# MKW38A4 register map
Vendor: NXP Semiconductors; Series: Kinetis_W; File version: 1.6
CPU: CM0PLUS r0p0, little endian, no MPU, no FPU, VTOR, 2 interrupt priority bits
Registers are 32-bit, read-write, no defined reset value unless marked. A register's access mark holds for its fields unless they carry their own. Offsets are from the block's base; [hi:lo] are bit positions; {n}, {i} and the like mark numbered series; 'fields as' and 'values as' point back to an identical list.

## XCVR_RX_DIG
Base 0x40087000
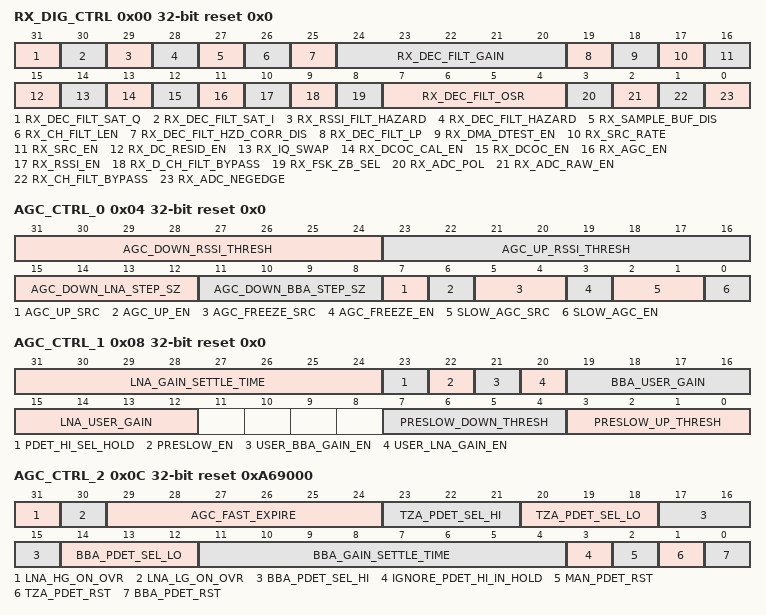
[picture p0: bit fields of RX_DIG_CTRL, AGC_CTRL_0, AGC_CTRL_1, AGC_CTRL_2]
0x00 RX_DIG_CTRL reset 0x0 — RX Digital Control
  [31] RX_DEC_FILT_SAT_Q ro — Decimator output, saturation detected for Q channel
    0=A saturation condition has not occurred; 1=A saturation condition has occurred
  [30] RX_DEC_FILT_SAT_I ro — Decimator output, saturation detected for I channel
    values as RX_DEC_FILT_SAT_Q
  [29] RX_RSSI_FILT_HAZARD ro — Decimator output for RSSI, hazard condition detected
    0=A hazard condition has not been detected; 1=A hazard condition has been detected
  [28] RX_DEC_FILT_HAZARD ro — Decimator output, hazard condition detected
    values as RX_RSSI_FILT_HAZARD
  [27] RX_SAMPLE_BUF_DIS — RX Sample Buffer Disable
    0=Buffer is enabled; 1=Buffer is disabled
  [26] RX_CH_FILT_LEN — RX Channel Filter Length
    0=Channel filter length is 24; 1=Channel filter length is 16. Only RX_CHF_COEF_4 - RX_CHF_COEF_11 are used in this mode.
  [25] RX_DEC_FILT_HZD_CORR_DIS — Decimator filter hazard correction disable
    0=Hazard correction is enabled; 1=Hazard correction is disabled
  [24:20] RX_DEC_FILT_GAIN — Decimation Filter Fractional Gain
  [19] RX_DEC_FILT_LP — RX Decimator Low Power
    0=Decimator operates in normal mode; 1=Decimator operates in low power mode
  [18] RX_DMA_DTEST_EN — RX DMA and DTEST enable
  [17] RX_SRC_RATE — RX Sample Rate Converter Rate Selections
    0=SRC is configured for a First Order Hold rate of 8/13; 1=SRC is configured for a Zero Order Hold rate of 12/13
  [16] RX_SRC_EN — RX Sample Rate Converter Enable
    0=SRC is disabled; 1=SRC is enabled
  [15] RX_DC_RESID_EN — DC Residual Enable
    0=DC Residual block is disabled; 1=DC Residual block is enabled
  [14] RX_IQ_SWAP
    0=IQ swap is disabled; 1=IQ swap is enabled
  [13] RX_DCOC_CAL_EN — DCOC Calibration Enable
    0=DCOC calibration is disabled; 1=DCOC calibration is enabled
  [12] RX_DCOC_EN — DCOC Enable
    0=DCOC is disabled; 1=DCOC is enabled
  [11] RX_AGC_EN — AGC Global Enable
    0=AGC is disabled; 1=AGC is enabled
  [10] RX_RSSI_EN — RSSI Measurement Enable
    0=RSSI measurement is disabled; 1=RSSI measurement is enabled
  [9] RX_D_CH_FILT_BYPASS — Receive Demod Channel Filter Bypass
    0=Demod channel filter is enabled; 1=Disable and bypass demod channel filter
  [8] RX_FSK_ZB_SEL — Demodulator select
    0=FSK demodulator
  [7:4] RX_DEC_FILT_OSR — Decimation Filter Oversampling
    0=OSR 4; 1=OSR 8; 2=OSR 16; 4=OSR 32; 8=OSR 64; 3=OSR 6; 5=OSR 12; 6=OSR 24; 7=OSR 48
  [3] RX_ADC_POL — Receive ADC Polarity
    0=ADC output of 1'b0 maps to -1, 1'b1 maps to +1 (default); 1=ADC output of 1'b0 maps to +1, 1'b1 maps to -1
  [2] RX_ADC_RAW_EN — ADC Raw Mode selection
    0=Normal operation; 1=The decimation filter's 12bit output consists of ADC samples in the 8 LSBs. This is for test purposes only to observe ADC output via XCVR DMA or DTEST.
  [1] RX_CH_FILT_BYPASS — Receive Channel Filter Bypass
    0=Channel filter is enabled; 1=Disable and bypass channel filter
  [0] RX_ADC_NEGEDGE — Receive ADC Negative Edge Selection
    0=Register ADC data on positive edge of clock; 1=Register ADC data on negative edge of clock
0x04 AGC_CTRL_0 reset 0x0 — AGC Control 0
  [31:24] AGC_DOWN_RSSI_THRESH — AGC DOWN RSSI Threshold
  [23:16] AGC_UP_RSSI_THRESH — AGC UP RSSI Threshold
  [15:12] AGC_DOWN_LNA_STEP_SZ
  [11:8] AGC_DOWN_BBA_STEP_SZ
  [7] AGC_UP_SRC — AGC Up Source
    0=PDET LO; 1=RSSI
  [6] AGC_UP_EN — AGC Up Enable
  [5:4] AGC_FREEZE_SRC — AGC Freeze Source Selection
    0=Access Address match (for active protocol); 1=Preamble Detect (for active protocol); 2=PD confirmation / Access Address match (for active protocol)
  [3] AGC_FREEZE_EN — AGC Freeze Enable
  [2:1] SLOW_AGC_SRC — Slow AGC Source Selection
    0=Access Address match (for active protocol); 1=Preamble Detect (for active protocol); 2=Fast AGC expire timer
  [0] SLOW_AGC_EN — Slow AGC Enable
0x08 AGC_CTRL_1 reset 0x0 — AGC Control 1
  [31:24] LNA_GAIN_SETTLE_TIME
  [23] PDET_HI_SEL_HOLD — AGC HOLD hysteresis
    0=Disabled; 1=Enabled
  [22] PRESLOW_EN — Pre-slow Enable
    0=Pre-slow is disabled; 1=Pre-slow is enabled
  [21] USER_BBA_GAIN_EN — User BBA Gain Enable
  [20] USER_LNA_GAIN_EN — User LNA Gain Enable
  [19:16] BBA_USER_GAIN
  [15:12] LNA_USER_GAIN
  [7:4] PRESLOW_DOWN_THRESH
  [3:0] PRESLOW_UP_THRESH
0x0C AGC_CTRL_2 reset 0xA69000 — AGC Control 2
  [31] LNA_HG_ON_OVR — LNA_HG_ON override
  [30] LNA_LG_ON_OVR — LNA_LG_ON override
  [29:24] AGC_FAST_EXPIRE
  [23:21] TZA_PDET_SEL_HI — TZA PDET Threshold High
    0=0.600V; 1=0.645V; 2=0.705V; 3=0.750V; 4=0.795V; 5=0.855V; 6=0.900V; 7=0.945V
  [20:18] TZA_PDET_SEL_LO — TZA PDET Threshold Low
    0=0.600V; 1=0.615V; 2=0.630V; 3=0.645V; 4=0.660V; 5=0.675V; 6=0.690V; 7=0.705V
  [17:15] BBA_PDET_SEL_HI — BBA PDET Threshold High
    0=0.600V; 1=0.795V; 2=0.900V; 3=0.945V; 4=1.005V; 5=1.050V; 6=1.095V; 7=1.155V
  [14:12] BBA_PDET_SEL_LO — BBA PDET Threshold Low
    values as TZA_PDET_SEL_LO
  [11:4] BBA_GAIN_SETTLE_TIME
  [3] IGNORE_PDET_HI_IN_HOLD — Ignore PDET_HI in HOLD State
  [2] MAN_PDET_RST — MAN PDET Reset
    0=The peak detector reset signals are controlled automatically by the AGC; 1=The BBA_PDET_RST and TZA_PDET_RST are used to manually control the peak detector reset signals
  [1] TZA_PDET_RST — TZA PDET Reset
  [0] BBA_PDET_RST — BBA PDET Reset
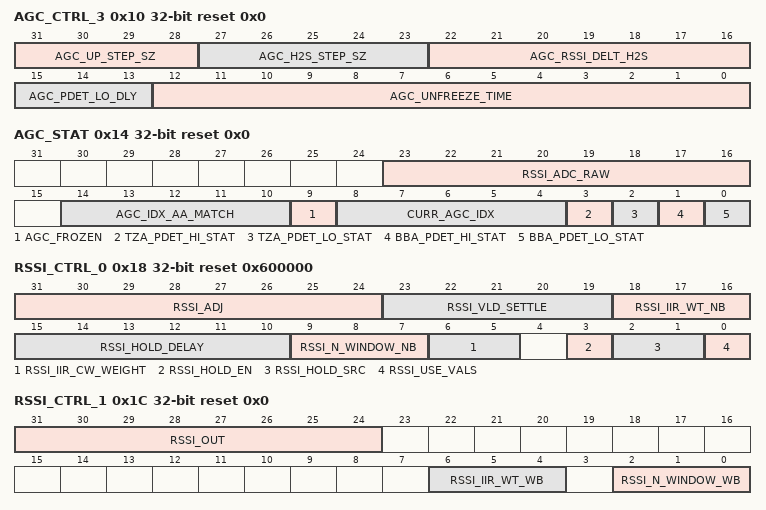
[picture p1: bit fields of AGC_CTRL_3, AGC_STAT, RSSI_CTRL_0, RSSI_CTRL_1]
0x10 AGC_CTRL_3 reset 0x0 — AGC Control 3
  [31:28] AGC_UP_STEP_SZ — AGC Up Step Size
  [27:23] AGC_H2S_STEP_SZ
  [22:16] AGC_RSSI_DELT_H2S
  [15:13] AGC_PDET_LO_DLY — AGC Peak Detect Low Delay
  [12:0] AGC_UNFREEZE_TIME
0x14 AGC_STAT ro reset 0x0 — AGC Status
  [23:16] RSSI_ADC_RAW — ADC RAW RSSI Reading
  [14:10] AGC_IDX_AA_MATCH — AGC Gain Index at AA Match
  [9] AGC_FROZEN — AGC Frozen Status
    0=AGC is not frozen; 1=AGC is frozen
  [8:4] CURR_AGC_IDX — Current AGC Gain Index
  [3] TZA_PDET_HI_STAT — TZA Peak Detector High Status
  [2] TZA_PDET_LO_STAT — TZA Peak Detector Low Status
  [1] BBA_PDET_HI_STAT — BBA Peak Detector High Status
  [0] BBA_PDET_LO_STAT — BBA Peak Detector Low Status
0x18 RSSI_CTRL_0 reset 0x600000 — RSSI Control 0
  [31:24] RSSI_ADJ — RSSI Adjustment
  [23:19] RSSI_VLD_SETTLE — RSSI Valid Settle
  [18:16] RSSI_IIR_WT_NB — RSSI IIR Weighting Narrowband
    0=Bypass; 1=1/2; 2=1/4; 3=1/8; 4=1/16; 5=1/32
  [15:10] RSSI_HOLD_DELAY
  [9:7] RSSI_N_WINDOW_NB — RSSI N Window Average Narrowband
    0=No averaging; 1=Averaging window length is 2 samples; 2=Averaging window length is 4 samples; 3=Averaging window length is 8 samples; 4=Averaging window length is 16 samples; 5=Averaging window length is 32 samples
  [6:5] RSSI_IIR_CW_WEIGHT — RSSI IIR CW Weighting
    0=Bypass; 1=1/8; 2=1/16; 3=1/32
  [3] RSSI_HOLD_EN — RSSI Hold Enable
  [2:1] RSSI_HOLD_SRC — RSSI Hold Source Selection
    0=Access Address match; 1=Preamble Detect
  [0] RSSI_USE_VALS — RSSI Values Selection
    0=RSSI calculation uses BBA_RES_TUNE_VAL registers; 1=RSSI calculation does not use BBA_RES_TUNE_VAL registers
0x1C RSSI_CTRL_1 reset 0x0 — RSSI Control 1
  [31:24] RSSI_OUT ro — RSSI Reading
  [6:4] RSSI_IIR_WT_WB — RSSI IIR Weighting Wideband
    0=Bypass; 1=1/2; 2=1/4; 3=1/8; 4=1/16; 5=1/32
  [2:0] RSSI_N_WINDOW_WB — RSSI N Window Average Wideband
    values as RSSI_CTRL_0.RSSI_N_WINDOW_NB
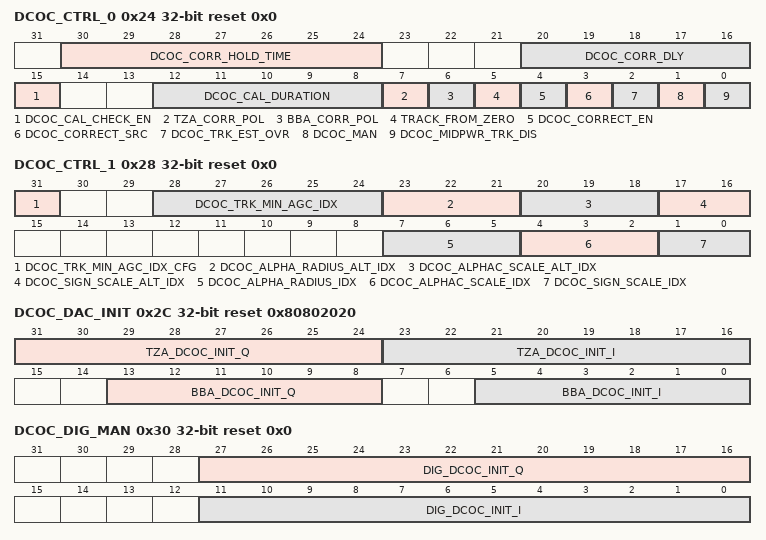
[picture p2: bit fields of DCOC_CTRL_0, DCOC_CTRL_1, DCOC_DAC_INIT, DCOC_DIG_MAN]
0x24 DCOC_CTRL_0 reset 0x0 — DCOC Control 0
  [30:24] DCOC_CORR_HOLD_TIME — DCOC Correction Hold Time
    127=The DC correction is not frozen
  [20:16] DCOC_CORR_DLY — DCOC Correction Delay
  [15] DCOC_CAL_CHECK_EN — DCOC Calibration Check Enable
    0=Calibration checking disabled. The DCOC_OFFSET_n registers are always updated during calibration.; 1=Calibration checking enabled. The DCOC_OFFSET_n registers are updated conditionally depending on the outcome of the pass/fail threshold checks performed on the alpha-hat and beta-hat estimates during calibration.
  [12:8] DCOC_CAL_DURATION — DCOC Calibration Duration
  [7] TZA_CORR_POL — TZA Correction Polarity
    0=Normal polarity; 1=Negative polarity. This should be set if the ADC output is inverted, or if the TZA DACs were implemented with negative polarity.
  [6] BBA_CORR_POL — BBA Correction Polarity
    0=Normal polarity; 1=Negative polarity. This should be set if the ADC output is inverted, or if the BBA DACs were implemented with negative polarity.
  [5] TRACK_FROM_ZERO
    0=Track from current I/Q sample; 1=Track from zero
  [4] DCOC_CORRECT_EN — DCOC Correction Enable
    0=Correction disabled. The DCOC will not correct the DC offset.; 1=Correction enabled. The DCOC will use the TZA and BBA DACs, and apply digital corrections (if DCOC_CORRECT_SRC=1) to correct the DC offset.
  [3] DCOC_CORRECT_SRC — DCOC Corrector Source
    0=If correction is enabled, the DCOC will use only the DCOC calibration table to correct the DC offset; 1=If correction is enabled, the DCOC will use the DCOC calibration table and then the tracking estimator to correct the DC offset
  [2] DCOC_TRK_EST_OVR — Override for the DCOC tracking estimator
    0=The tracking estimator is enabled only as needed by the corrector; 1=The tracking estimator remains enabled whenever the DCOC is active
  [1] DCOC_MAN — DCOC Manual Override
  [0] DCOC_MIDPWR_TRK_DIS — DCOC Mid Power Tracking Disable
    0=Tracking corrections are enabled as determined by DCOC_CORRECT_SRC and DCOC_TRK_MIN_AGC_IDX; 1=Tracking corrections are disabled when either the TZA or BBA lo peak detector asserts
0x28 DCOC_CTRL_1 reset 0x0 — DCOC Control 1
  [31] DCOC_TRK_MIN_AGC_IDX_CFG — DCOC_TRK_MIN_AGC_IDX Configuration
    0=Tracking is disabled when the AGC index is less than DCOC_TRK_MIN_AGC_IDX; 1=Tracking is enabled when AGC index is less than DCOC_TRK_MIN_AGC_IDX, but {DCOC_CORR_DLY_ALT, DCOC_CORR_HOLD_TIME_ALT, DCOC_ALPHA_RADIUS_ALT_IDX, DCOC_ALPHAC_SCALE_ALT_IDX, DCOC_SIGN_SCALE_ALT_IDX} are used instead of {DCOC_CORR_DLY, DCOC_CORR_HOLD_TIME, DCOC_ALPHA_RADIUS_IDX, DCOC_ALPHAC_SCALE_IDX, DCOC_SIGN_SCALE_IDX}
  [28:24] DCOC_TRK_MIN_AGC_IDX — DCOC Tracking Minimum AGC Table Index
  [23:21] DCOC_ALPHA_RADIUS_ALT_IDX — Alpha-R Scaling Alternate
    0=1; 1=1/2; 2=1/4; 3=1/8; 4=1/16; 5=1/32; 6=1/64
  [20:18] DCOC_ALPHAC_SCALE_ALT_IDX — DCOC Alpha-C Scaling Alternate
    0=1/2; 1=1/4; 2=1/8; 3=1/16; 4=1/32; 5=1/64
  [17:16] DCOC_SIGN_SCALE_ALT_IDX — DCOC Sign Scaling Alternate
    0=1/8; 1=1/16; 2=1/32; 3=1/64
  [7:5] DCOC_ALPHA_RADIUS_IDX — Alpha-R Scaling
    0=1; 1=1/2; 2=1/4; 3=1/8; 4=1/16; 5=1/32; 6=1/64
  [4:2] DCOC_ALPHAC_SCALE_IDX — DCOC Alpha-C Scaling
    0=1/2; 1=1/4; 2=1/8; 3=1/16; 4=1/32; 5=1/64
  [1:0] DCOC_SIGN_SCALE_IDX — DCOC Sign Scaling
    0=1/8; 1=1/16; 2=1/32; 3=1/64
0x2C DCOC_DAC_INIT reset 0x80802020 — DCOC DAC Initialization
  [31:24] TZA_DCOC_INIT_Q — DCOC TZA Init Q
  [23:16] TZA_DCOC_INIT_I — DCOC TZA Init I
  [13:8] BBA_DCOC_INIT_Q — DCOC BBA Init Q
  [5:0] BBA_DCOC_INIT_I — DCOC BBA Init I
0x30 DCOC_DIG_MAN reset 0x0 — DCOC Digital Correction Manual Override
  [27:16] DIG_DCOC_INIT_Q — DCOC DIG Init Q
  [11:0] DIG_DCOC_INIT_I — DCOC DIG Init I
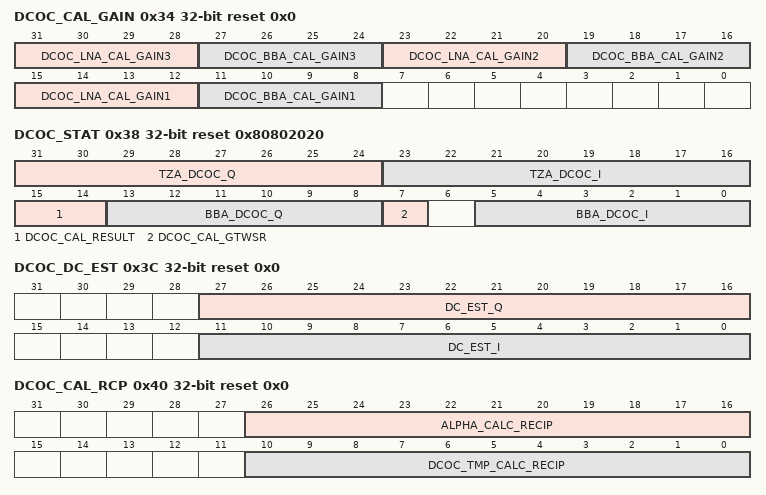
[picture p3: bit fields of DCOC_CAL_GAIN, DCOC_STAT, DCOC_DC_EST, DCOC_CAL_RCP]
0x34 DCOC_CAL_GAIN reset 0x0 — DCOC Calibration Gain
  [31:28] DCOC_LNA_CAL_GAIN3 — DCOC LNA Calibration Gain 3
  [27:24] DCOC_BBA_CAL_GAIN3 — DCOC BBA Calibration Gain 3
  [23:20] DCOC_LNA_CAL_GAIN2 — DCOC LNA Calibration Gain 2
  [19:16] DCOC_BBA_CAL_GAIN2 — DCOC BBA Calibration Gain 2
  [15:12] DCOC_LNA_CAL_GAIN1 — DCOC LNA Calibration Gain 1
  [11:8] DCOC_BBA_CAL_GAIN1 — DCOC BBA Calibration Gain 1
0x38 DCOC_STAT ro reset 0x80802020 — DCOC Status
  [31:24] TZA_DCOC_Q — DCOC TZA DAC Q
  [23:16] TZA_DCOC_I — DCOC TZA DAC I
  [15:14] DCOC_CAL_RESULT
    0=Calibration checks failed. DCOC_OFFSET_n tables not updated.; 1=Calibration checks neither passed nor failed, DCOC_OFFSET_n tables not updated; 2=Calibration checks neither passed nor failed, DCOC_OFFSET_n tables updated since no previous Pass condition has occurred since the last radio reset; 3=Calibration checks passed. DCOC_OFFSET_n tables updated
  [13:8] BBA_DCOC_Q — DCOC BBA DAC Q
  [7] DCOC_CAL_GTWSR — DCOC calibration Good Table Written Since Reset
    0=A Passing calibration result has not occurred since the last radio reset; 1=A Passing calibration result has occurred since the last radio reset
  [5:0] BBA_DCOC_I — DCOC BBA DAC I
0x3C DCOC_DC_EST ro reset 0x0 — DCOC DC Estimate
  [27:16] DC_EST_Q — DCOC DC Estimate Q
  [11:0] DC_EST_I — DCOC DC Estimate I
0x40 DCOC_CAL_RCP reset 0x0 — DCOC Calibration Reciprocals
  [26:16] ALPHA_CALC_RECIP — Alpha Calculation Reciprocal
  [10:0] DCOC_TMP_CALC_RECIP — DCOC Calculation Reciprocal
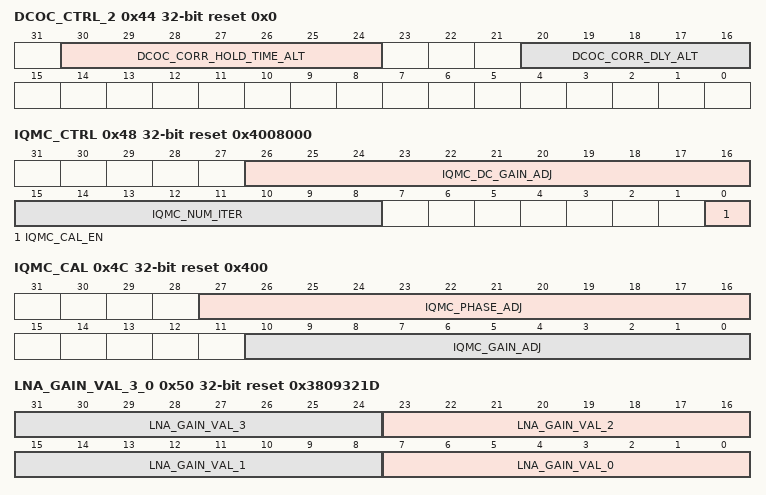
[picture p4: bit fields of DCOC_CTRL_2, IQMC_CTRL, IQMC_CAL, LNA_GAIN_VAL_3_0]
0x44 DCOC_CTRL_2 reset 0x0 — DCOC Control 2
  [30:24] DCOC_CORR_HOLD_TIME_ALT — DCOC Correction Hold Time Alternate
    127=The DC correction is not frozen
  [20:16] DCOC_CORR_DLY_ALT — DCOC Correction Delay Alternate
0x48 IQMC_CTRL reset 0x4008000 — IQMC Control
  [26:16] IQMC_DC_GAIN_ADJ — IQ Mismatch Correction DC Gain Coeff
  [15:8] IQMC_NUM_ITER — IQ Mismatch Cal Num Iter
  [0] IQMC_CAL_EN — IQ Mismatch Cal Enable
0x4C IQMC_CAL reset 0x400 — IQMC Calibration
  [27:16] IQMC_PHASE_ADJ — IQ Mismatch Correction Phase Coeff
  [10:0] IQMC_GAIN_ADJ — IQ Mismatch Correction Gain Coeff
0x50 LNA_GAIN_VAL_3_0 reset 0x3809321D — LNA_GAIN Step Values 3..0
  [8n+7:8n] LNA_GAIN_VAL_{n} (n=0..3) — LNA_GAIN step {n}
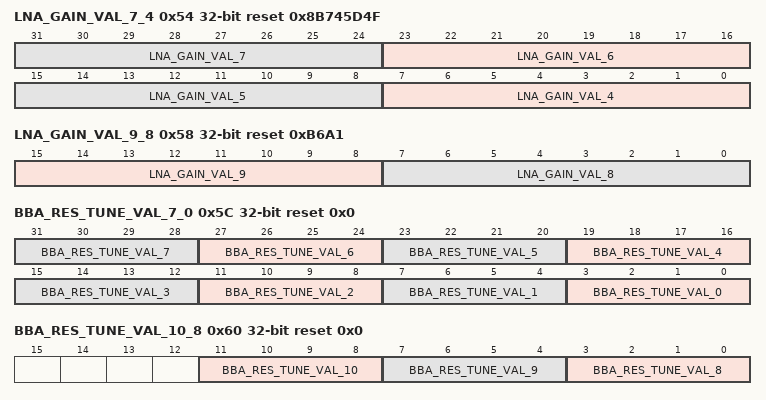
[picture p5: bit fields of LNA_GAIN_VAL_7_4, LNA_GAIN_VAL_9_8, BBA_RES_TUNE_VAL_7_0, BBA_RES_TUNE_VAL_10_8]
0x54 LNA_GAIN_VAL_7_4 reset 0x8B745D4F — LNA_GAIN Step Values 7..4
  [8n-25:8n-32] LNA_GAIN_VAL_{n} (n=4..7) — LNA_GAIN step {n}
0x58 LNA_GAIN_VAL_9_8 reset 0xB6A1 — LNA_GAIN Step Values 9..8
  [15:8] LNA_GAIN_VAL_9 — LNA_GAIN step 9
  [7:0] LNA_GAIN_VAL_8 — LNA_GAIN step 8
0x5C BBA_RES_TUNE_VAL_7_0 reset 0x0 — BBA Resistor Tune Values 7..0
  [4n+3:4n] BBA_RES_TUNE_VAL_{n} (n=0..7) — BBA Resistor Tune Step {n}
0x60 BBA_RES_TUNE_VAL_10_8 reset 0x0 — BBA Resistor Tune Values 10..8
  [11:8] BBA_RES_TUNE_VAL_10 — BBA Resistor Tune Step 10
  [7:4] BBA_RES_TUNE_VAL_9 — BBA Resistor Tune Step 9
  [3:0] BBA_RES_TUNE_VAL_8 — BBA Resistor Tune Step 8
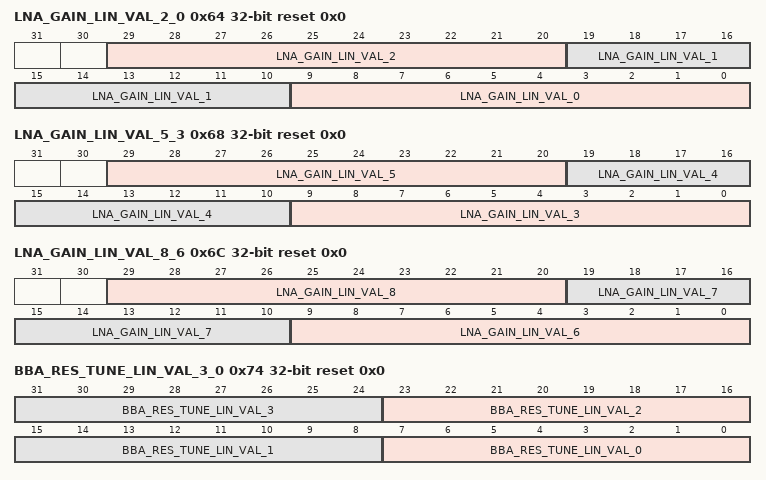
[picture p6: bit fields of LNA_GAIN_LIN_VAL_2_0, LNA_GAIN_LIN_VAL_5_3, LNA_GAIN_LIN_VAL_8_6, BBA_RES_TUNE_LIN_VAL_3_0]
0x64 LNA_GAIN_LIN_VAL_2_0 reset 0x0 — LNA Linear Gain Values 2..0
  [29:20] LNA_GAIN_LIN_VAL_2 — LNA Linear Gain Step 2
  [19:10] LNA_GAIN_LIN_VAL_1 — LNA Linear Gain Step 1
  [9:0] LNA_GAIN_LIN_VAL_0 — LNA Linear Gain Step 0
0x68 LNA_GAIN_LIN_VAL_5_3 reset 0x0 — LNA Linear Gain Values 5..3
  [29:20] LNA_GAIN_LIN_VAL_5 — LNA Linear Gain Step 5
  [19:10] LNA_GAIN_LIN_VAL_4 — LNA Linear Gain Step 4
  [9:0] LNA_GAIN_LIN_VAL_3 — LNA Linear Gain Step 3
0x6C LNA_GAIN_LIN_VAL_8_6 reset 0x0 — LNA Linear Gain Values 8..6
  [29:20] LNA_GAIN_LIN_VAL_8 — LNA Linear Gain Step 8
  [19:10] LNA_GAIN_LIN_VAL_7 — LNA Linear Gain Step 7
  [9:0] LNA_GAIN_LIN_VAL_6 — LNA Linear Gain Step 6
0x70 LNA_GAIN_LIN_VAL_9 reset 0x0 — LNA Linear Gain Values 9
  [9:0] LNA_GAIN_LIN_VAL_9 — LNA Linear Gain Step 9
0x74 BBA_RES_TUNE_LIN_VAL_3_0 reset 0x0 — BBA Resistor Tune Values 3..0
  [8n+7:8n] BBA_RES_TUNE_LIN_VAL_{n} (n=0..3) — BBA Resistor Tune Linear Gain Step {n}
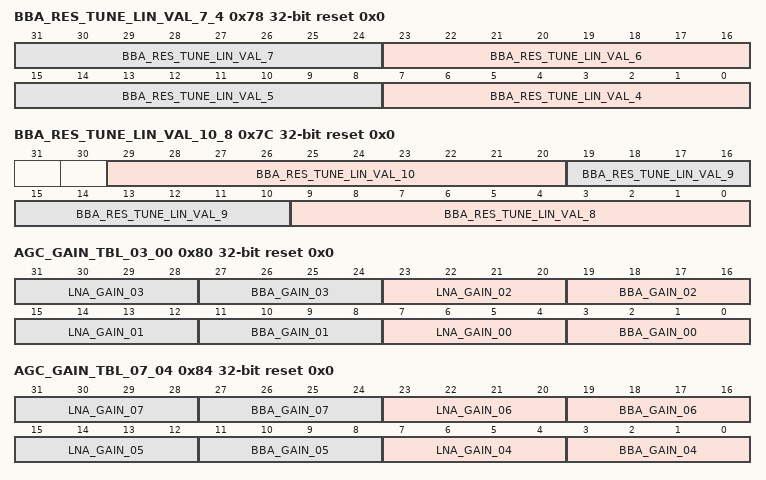
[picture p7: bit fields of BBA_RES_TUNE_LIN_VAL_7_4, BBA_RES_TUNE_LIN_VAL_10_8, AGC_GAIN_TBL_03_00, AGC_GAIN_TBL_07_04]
0x78 BBA_RES_TUNE_LIN_VAL_7_4 reset 0x0 — BBA Resistor Tune Values 7..4
  [8n-25:8n-32] BBA_RES_TUNE_LIN_VAL_{n} (n=4..7) — BBA Resistor Tune Linear Gain Step {n}
0x7C BBA_RES_TUNE_LIN_VAL_10_8 reset 0x0 — BBA Resistor Tune Values 10..8
  [29:20] BBA_RES_TUNE_LIN_VAL_10 — BBA Resistor Tune Linear Gain Step 10
  [19:10] BBA_RES_TUNE_LIN_VAL_9 — BBA Resistor Tune Linear Gain Step 9
  [9:0] BBA_RES_TUNE_LIN_VAL_8 — BBA Resistor Tune Linear Gain Step 8
0x80 AGC_GAIN_TBL_03_00 reset 0x0 — AGC Gain Tables Step 03..00
  [8n+7:8n+4] LNA_GAIN_{n:02} (n=0..3), [8n+3:8n] BBA_GAIN_{n:02} (n=0..3)
0x84 AGC_GAIN_TBL_07_04 reset 0x0 — AGC Gain Tables Step 07..04
  [8n-25:8n-28] LNA_GAIN_{n:02} (n=4..7), [8n-29:8n-32] BBA_GAIN_{n:02} (n=4..7)
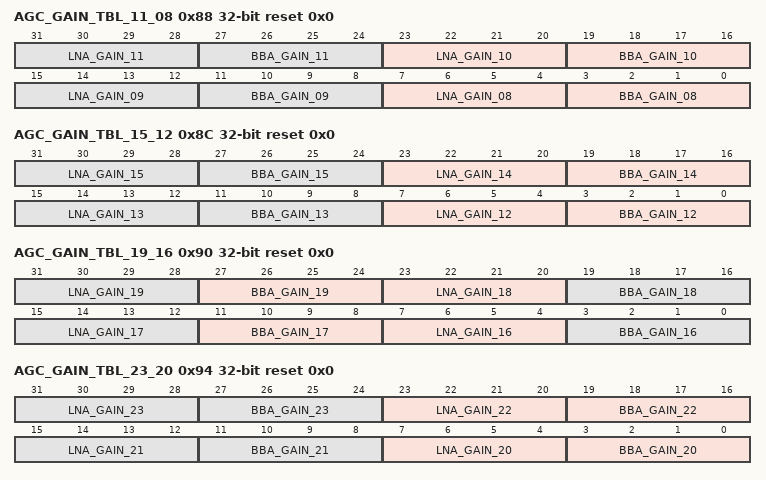
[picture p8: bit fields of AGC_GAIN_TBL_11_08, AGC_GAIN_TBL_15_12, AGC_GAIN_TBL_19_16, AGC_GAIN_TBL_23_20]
0x88 AGC_GAIN_TBL_11_08 reset 0x0 — AGC Gain Tables Step 11..08
  [8n-57:8n-60] LNA_GAIN_{n:02} (n=8..11), [8n-61:8n-64] BBA_GAIN_{n:02} (n=8..11)
0x8C AGC_GAIN_TBL_15_12 reset 0x0 — AGC Gain Tables Step 15..12
  [8n-89:8n-92] LNA_GAIN_{n} (n=12..15), [8n-93:8n-96] BBA_GAIN_{n} (n=12..15)
0x90 AGC_GAIN_TBL_19_16 reset 0x0 — AGC Gain Tables Step 19..16
  [8n-121:8n-124] LNA_GAIN_{n} (n=16..19)
  [27:24] BBA_GAIN_19 — BBA Gain 193
  [19:16] BBA_GAIN_18
  [11:8] BBA_GAIN_17
  [3:0] BBA_GAIN_16
0x94 AGC_GAIN_TBL_23_20 reset 0x0 — AGC Gain Tables Step 23..20
  [8n-153:8n-156] LNA_GAIN_{n} (n=20..23), [8n-157:8n-160] BBA_GAIN_{n} (n=20..23)
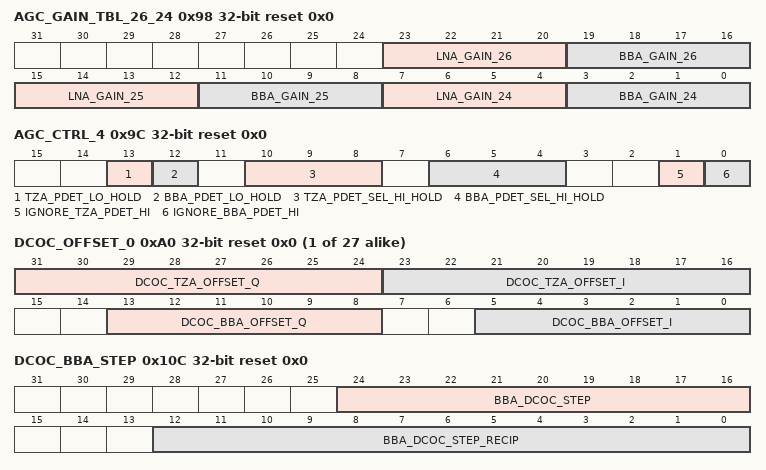
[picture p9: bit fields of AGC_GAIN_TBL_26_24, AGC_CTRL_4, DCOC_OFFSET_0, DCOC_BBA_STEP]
0x98 AGC_GAIN_TBL_26_24 reset 0x0 — AGC Gain Tables Step 26..24
  [23:20] LNA_GAIN_26, [19:16] BBA_GAIN_26, [15:12] LNA_GAIN_25, [11:8] BBA_GAIN_25, [7:4] LNA_GAIN_24, [3:0] BBA_GAIN_24
0x9C AGC_CTRL_4 reset 0x0 — AGC Control 4
  [13] TZA_PDET_LO_HOLD
  [12] BBA_PDET_LO_HOLD
  [10:8] TZA_PDET_SEL_HI_HOLD
  [6:4] BBA_PDET_SEL_HI_HOLD
  [1] IGNORE_TZA_PDET_HI — Ignore TZA Peak Detector High when in AGC Hold
  [0] IGNORE_BBA_PDET_HI — Ignore BBA Peak Detector High when in AGC Hold
{0xA0+4i} DCOC_OFFSET_{i} reset 0x0 (i=0..26) — DCOC Offset
  [31:24] DCOC_TZA_OFFSET_Q — DCOC TZA Q-channel offset
  [23:16] DCOC_TZA_OFFSET_I — DCOC TZA I-channel offset
  [13:8] DCOC_BBA_OFFSET_Q — DCOC BBA Q-channel offset
  [5:0] DCOC_BBA_OFFSET_I — DCOC BBA I-channel offset
0x10C DCOC_BBA_STEP reset 0x0 — DCOC BBA DAC Step
  [24:16] BBA_DCOC_STEP — DCOC BBA Step Size
  [12:0] BBA_DCOC_STEP_RECIP — DCOC BBA Reciprocal of Step Size
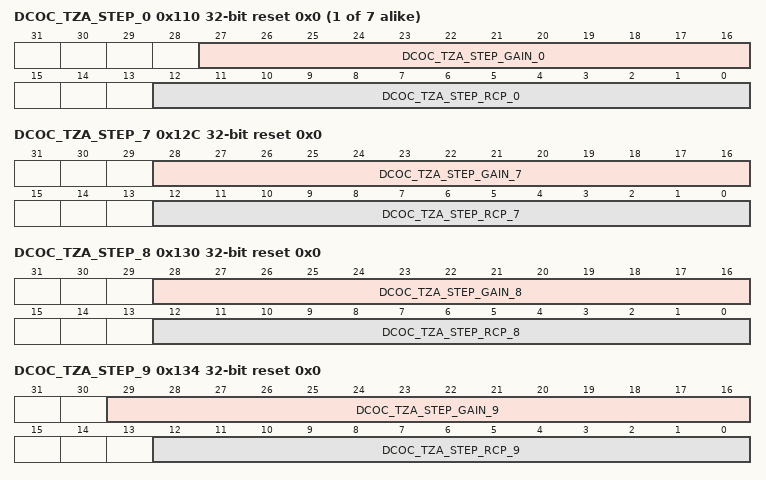
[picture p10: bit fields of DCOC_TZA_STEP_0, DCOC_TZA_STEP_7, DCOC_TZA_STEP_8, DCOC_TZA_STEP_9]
{0x110+4i} DCOC_TZA_STEP_{i} reset 0x0 (i=0..6) — DCOC TZA DAC Step {i}
  [27:16] DCOC_TZA_STEP_GAIN_{i}, [12:0] DCOC_TZA_STEP_RCP_{i}
0x12C DCOC_TZA_STEP_7 reset 0x0 — DCOC TZA DAC Step 7
  [28:16] DCOC_TZA_STEP_GAIN_7, [12:0] DCOC_TZA_STEP_RCP_7
0x130 DCOC_TZA_STEP_8 reset 0x0 — DCOC TZA DAC Step 5
  [28:16] DCOC_TZA_STEP_GAIN_8, [12:0] DCOC_TZA_STEP_RCP_8
0x134 DCOC_TZA_STEP_9 reset 0x0 — DCOC TZA DAC Step 9
  [29:16] DCOC_TZA_STEP_GAIN_9, [12:0] DCOC_TZA_STEP_RCP_9
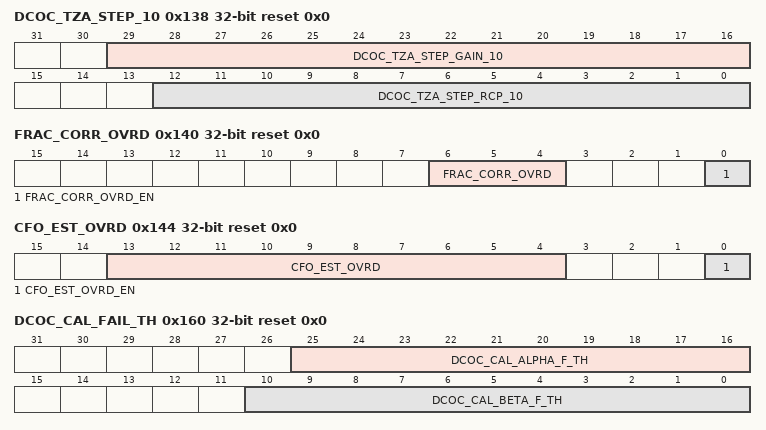
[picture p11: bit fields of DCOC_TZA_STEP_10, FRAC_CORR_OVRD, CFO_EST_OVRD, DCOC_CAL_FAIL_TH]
0x138 DCOC_TZA_STEP_10 reset 0x0 — DCOC TZA DAC Step 10
  [29:16] DCOC_TZA_STEP_GAIN_10, [12:0] DCOC_TZA_STEP_RCP_10
0x140 FRAC_CORR_OVRD reset 0x0 — FRAC CORR Override
  [6:4] FRAC_CORR_OVRD — FRAC CORR Override Value
  [0] FRAC_CORR_OVRD_EN — FRAC CORR Override Enable
0x144 CFO_EST_OVRD reset 0x0 — CFO Estimate Override
  [13:4] CFO_EST_OVRD — CFO Estimate Override Value
  [0] CFO_EST_OVRD_EN — CFO Estimate Override Enable
0x148 RX_D_CHF_COEF_0 reset 0x0 — Receive Demod Channel Filter Coef 0
  [8:0] RX_D_CH_FILT_H0 — RX Demod Channel Filter Coefficient 0
0x14C RX_D_CHF_COEF_1 reset 0x0 — Receive Demod Channel Filter Coef 1
  [8:0] RX_D_CH_FILT_H1 — RX Demod Channel Filter Coefficient 1
{0x148+4i} RX_D_CHF_COEF_{i} reset 0x0 (i=2..4) — Receive Demod Channel Filter Coef {i}
  [9:0] RX_D_CH_FILT_H{i} — RX Demod Channel Filter Coefficient {i}
0x160 DCOC_CAL_FAIL_TH reset 0x0 — DCOC Calibration Fail Thresholds
  [25:16] DCOC_CAL_ALPHA_F_TH — DCOC Calibration Alpha Fail Threshold
  [10:0] DCOC_CAL_BETA_F_TH — DCOC Calibration Beta Fail Threshold
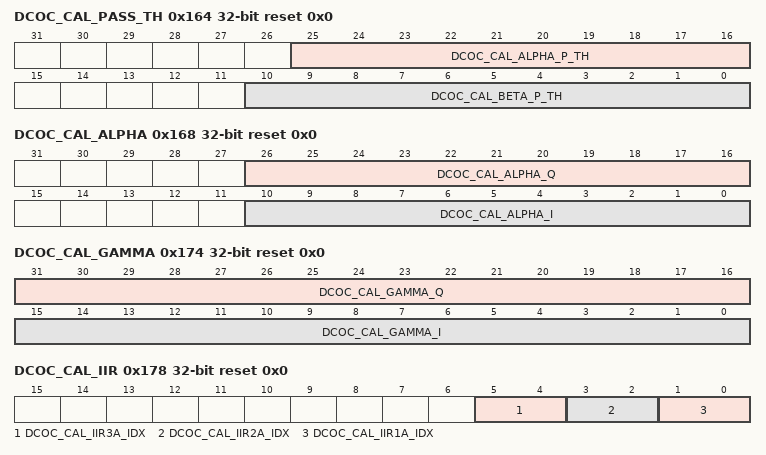
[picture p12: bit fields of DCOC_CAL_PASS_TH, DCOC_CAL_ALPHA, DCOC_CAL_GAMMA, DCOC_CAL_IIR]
0x164 DCOC_CAL_PASS_TH reset 0x0 — DCOC Calibration Pass Thresholds
  [25:16] DCOC_CAL_ALPHA_P_TH — DCOC Calibration Alpha Pass Threshold
  [10:0] DCOC_CAL_BETA_P_TH — DCOC Calibration Beta Pass Threshold
0x168 DCOC_CAL_ALPHA ro reset 0x0 — DCOC Calibration Alpha
  [26:16] DCOC_CAL_ALPHA_Q
  [10:0] DCOC_CAL_ALPHA_I — DCOC Calibration I-channel ALPHA constant
0x16C DCOC_CAL_BETA_Q ro reset 0x0 — DCOC Calibration Beta Q
  [16:0] DCOC_CAL_BETA_Q
0x170 DCOC_CAL_BETA_I ro reset 0x0 — DCOC Calibration Beta I
  [16:0] DCOC_CAL_BETA_I
0x174 DCOC_CAL_GAMMA ro reset 0x0 — DCOC Calibration Gamma
  [31:16] DCOC_CAL_GAMMA_Q, [15:0] DCOC_CAL_GAMMA_I
0x178 DCOC_CAL_IIR reset 0x0 — DCOC Calibration IIR
  [5:4] DCOC_CAL_IIR3A_IDX — DCOC Calibration IIR 3A Index
    0=1/4; 1=1/8; 2=1/16; 3=1/32
  [3:2] DCOC_CAL_IIR2A_IDX — DCOC Calibration IIR 2A Index
    0=1/1; 1=1/4; 2=1/8; 3=1/16
  [1:0] DCOC_CAL_IIR1A_IDX — DCOC Calibration IIR 1A Index
    0=1/1; 1=1/4; 2=1/8; 3=1/16
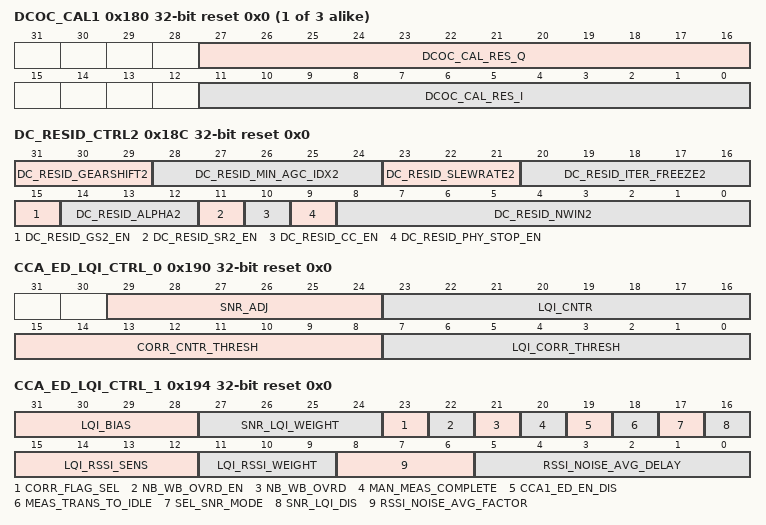
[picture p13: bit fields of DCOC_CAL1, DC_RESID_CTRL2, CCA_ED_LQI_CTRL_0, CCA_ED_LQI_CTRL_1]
{0x17C+4i} DCOC_CAL{i} ro reset 0x0 (i=1..3) — DCOC Calibration Result
  [27:16] DCOC_CAL_RES_Q — DCOC Calibration Result - Q Channel
  [11:0] DCOC_CAL_RES_I — DCOC Calibration Result - I Channel
0x18C DC_RESID_CTRL2 reset 0x0 — DC Residual Control2
  [31:29] DC_RESID_GEARSHIFT2 — DC Residual Gearshift, for Second Run
  [28:24] DC_RESID_MIN_AGC_IDX2 — DC Residual Minimum AGC Table Index, for Second Run
  [23:21] DC_RESID_SLEWRATE2 — DC Residual Slewrate, for Second Run
  [20:16] DC_RESID_ITER_FREEZE2 — DC Residual Iteration Freeze, for Second Run
  [15] DC_RESID_GS2_EN — DC Residual Gearshift Enable, for Second Run
    0=Gearshifting disabled for Second Run; 1=Gearshifting enabled for Second Run
  [14:12] DC_RESID_ALPHA2 — DC Residual Alpha, for Second Run
    0=Update factor is 1; 1=Update factor is 1/2; 2=Update factor is 1/4 + 1/8; 3=Update factor is 1/4; 4=Update factor is 1/8 + 16; 5=Update factor is 1/8; 6=Update factor is 1/16 + 1/32; 7=Update factor is 1/16
  [11] DC_RESID_SR2_EN — DC Residual Slewrate Enable, for Second Run
  [10] DC_RESID_CC_EN — DC Residual Continuous Correction Enable
  [9] DC_RESID_PHY_STOP_EN — DC Residual PHY Stop Enable
  [8:0] DC_RESID_NWIN2 — DC Residual NWIN, for Second Run
0x190 CCA_ED_LQI_CTRL_0 reset 0x0 — RX_DIG CCA ED LQI Control Register 0
  [29:24] SNR_ADJ — SNR calculation adjustment
  [23:16] LQI_CNTR — LQI Counter
  [15:8] CORR_CNTR_THRESH — Correlation Count Threshold
  [7:0] LQI_CORR_THRESH — LQI Correlation Threshold
0x194 CCA_ED_LQI_CTRL_1 reset 0x0 — RX_DIG CCA ED LQI Control Register 1
  [31:28] LQI_BIAS
  [27:24] SNR_LQI_WEIGHT
    0=0.0; 1=1.0; 2=1.125; 3=1.25; 4=1.375; 5=1.5; 6=1.625; 7=1.75; 8=1.875; 9=2.0; 10=2.125; 11=2.25; 12=2.375; 13=2.5; 14=2.625; 15=2.75
  [23] CORR_FLAG_SEL
    0=Internal (RXDIG-generated correlation flag); 1=External (PHY-generated correlation flag)
  [22] NB_WB_OVRD_EN — Narrowband Wideband Override Enable
    0=Normal operation; 1=RSSI narrowband/wideband selection is via NB_WB_OVRD
  [21] NB_WB_OVRD — Narrowband Wideband Override
    0=RSSI forced to be in Wideband mode if NB_WB_OVRD_EN is set; 1=RSSI forced to be in Narrowband mode if NB_WB_OVRD_EN is set
  [20] MAN_MEAS_COMPLETE — Manual measurement complete
    0=Normal operation; 1=Manually asserts the measurement complete signal for the RX_DIG CCA/ED/LQI blocks. Intended to be used only for debug.
  [19] CCA1_ED_EN_DIS — CCA1_ED_EN Disable
    0=Normal operation; 1=CCA1_ED_EN input is disabled
  [18] MEAS_TRANS_TO_IDLE — Measurement Transition to IDLE
    0=Module transitions to RSSI state; 1=Module transitions to IDLE state
  [17] SEL_SNR_MODE — Select SNR Mode
    0=SNR estimate; 1=Mapped correlation magnitude
  [16] SNR_LQI_DIS — SNR LQI Disable
    0=Normal operation; 1=The RX_DIG CCA/ED/LQI block ignores the AA match input which starts an LQI measurement
  [15:12] LQI_RSSI_SENS — LQI RSSI Sensitivity
  [11:9] LQI_RSSI_WEIGHT
    0=2.0; 1=2.125; 2=2.25; 3=2.375; 4=2.5; 5=2.625; 6=2.75; 7=2.875
  [8:6] RSSI_NOISE_AVG_FACTOR — RSSI Noise Averaging Factor
    0=1; 1=64; 2=70; 3=128; 4=139; 5=256; 6=277; 7=512
  [5:0] RSSI_NOISE_AVG_DELAY — RSSI Noise Averaging Delay
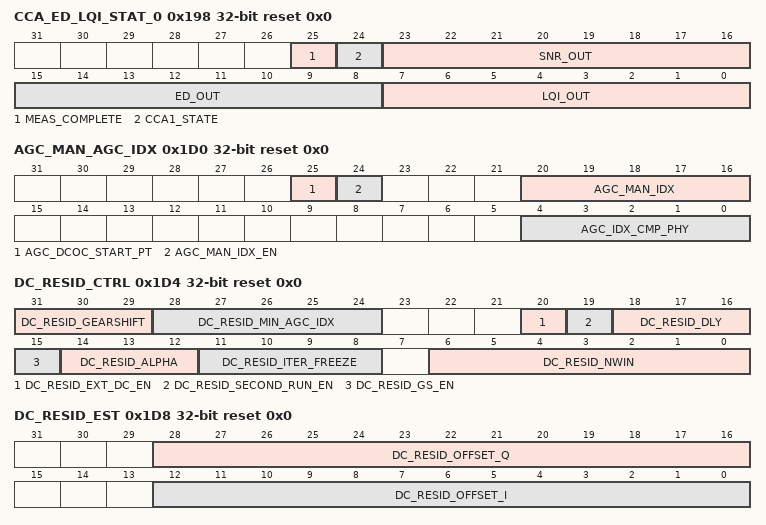
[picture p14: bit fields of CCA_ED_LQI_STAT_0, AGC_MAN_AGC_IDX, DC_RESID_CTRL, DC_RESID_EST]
0x198 CCA_ED_LQI_STAT_0 ro reset 0x0 — RX_DIG CCA ED LQI Status Register 0
  [25] MEAS_COMPLETE — Measurement Complete
  [24] CCA1_STATE
  [23:16] SNR_OUT — SNR output
  [15:8] ED_OUT — ED output
  [7:0] LQI_OUT — LQI output
0x1A0 RX_CHF_COEF_0 reset 0x0 — Receive Channel Filter Coefficient 0
  [5:0] RX_CH_FILT_H0 — RX Channel Filter Coefficient 0
0x1A4 RX_CHF_COEF_1 reset 0x0 — Receive Channel Filter Coefficient 1
  [5:0] RX_CH_FILT_H1 — RX Channel Filter Coefficient 1
{0x1A0+4i} RX_CHF_COEF_{i} reset 0x0 (i=2..5) — Receive Channel Filter Coefficient {i}
  [6:0] RX_CH_FILT_H{i} — RX Channel Filter Coefficient {i}
0x1B8 RX_CHF_COEF_6 reset 0x0 — Receive Channel Filter Coefficient 6
  [7:0] RX_CH_FILT_H6 — RX Channel Filter Coefficient 6
0x1BC RX_CHF_COEF_7 reset 0x0 — Receive Channel Filter Coefficient 7
  [7:0] RX_CH_FILT_H7 — RX Channel Filter Coefficient 7
0x1C0 RX_CHF_COEF_8 reset 0x0 — Receive Channel Filter Coefficient 8
  [8:0] RX_CH_FILT_H8 — RX Channel Filter Coefficient 8
0x1C4 RX_CHF_COEF_9 reset 0x0 — Receive Channel Filter Coefficient 9
  [8:0] RX_CH_FILT_H9 — RX Channel Filter Coefficient 9
0x1C8 RX_CHF_COEF_10 reset 0x0 — Receive Channel Filter Coefficient 10
  [9:0] RX_CH_FILT_H10 — RX Channel Filter Coefficient 10
0x1CC RX_CHF_COEF_11 reset 0x0 — Receive Channel Filter Coefficient 11
  [9:0] RX_CH_FILT_H11 — RX Channel Filter Coefficient 11
0x1D0 AGC_MAN_AGC_IDX reset 0x0 — AGC Manual AGC Index
  [25] AGC_DCOC_START_PT — AGC DCOC Start Point
  [24] AGC_MAN_IDX_EN — AGC Manual Index Enable
  [20:16] AGC_MAN_IDX — AGC Manual Index
  [4:0] AGC_IDX_CMP_PHY — AGC Index Compare threshold for PHY
0x1D4 DC_RESID_CTRL reset 0x0 — DC Residual Control
  [31:29] DC_RESID_GEARSHIFT — DC Residual Gearshift
  [28:24] DC_RESID_MIN_AGC_IDX — DC Residual Minimum AGC Table Index
  [20] DC_RESID_EXT_DC_EN — DC Residual External DC Enable
  [19] DC_RESID_SECOND_RUN_EN — DC Residual Second Run Enable
    0=Second Run disabled; 1=Second Run enabled
  [18:16] DC_RESID_DLY — DC Residual Delay
  [15] DC_RESID_GS_EN — DC Residual Gearshift Enable
    0=Gearshifting disabled; 1=Gearshifting enabled
  [14:12] DC_RESID_ALPHA — DC Residual Alpha
    values as DC_RESID_CTRL2.DC_RESID_ALPHA2
  [11:8] DC_RESID_ITER_FREEZE — DC Residual Iteration Freeze
  [6:0] DC_RESID_NWIN — DC Residual NWIN
0x1D8 DC_RESID_EST ro reset 0x0 — DC Residual Estimate
  [28:16] DC_RESID_OFFSET_Q — DC Residual Offset Q
  [12:0] DC_RESID_OFFSET_I — DC Residual Offset I
0x1DC RX_RCCAL_CTRL0 reset 0x0 — RX RC Calibration Control0
  [25] TZA_RCCAL_DIS — TZA RC Calibration Disable
    0=TZA RC Calibration is enabled; 1=TZA RC Calibration is disabled
  [24:20] TZA_RCCAL_MANUAL — TZA RC Calibration manual value
  [19:16] TZA_RCCAL_OFFSET — TZA RC Calibration value offset
  [15] RCCAL_COMP_INV — RC Calibration comp_out Invert
    0=The comp_out signal polarity is NOT inverted; 1=The comp_out signal polarity is inverted
  [13:12] RCCAL_SMP_DLY — RC Calibration Sample Delay
    {v}=The comp_out signal is sampled {v} clk cycle after sample signal is deasserted (v=0..3)
  [9] BBA_RCCAL_DIS — BBA RC Calibration Disable
    0=BBA RC Calibration is enabled; 1=BBA RC Calibration is disabled
  [8:4] BBA_RCCAL_MANUAL — BBA RC Calibration manual value
  [3:0] BBA_RCCAL_OFFSET — BBA RC Calibration value offset
0x1E0 RX_RCCAL_CTRL1 reset 0x0 — RX RC Calibration Control1
  [25] BBA2_RCCAL_DIS — BBA2 RC Calibration Disable
    0=BBA2 RC Calibration is enabled; 1=BBA2 RC Calibration is disabled
  [24:20] BBA2_RCCAL_MANUAL — BBA2 RC Calibration manual value
  [19:16] BBA2_RCCAL_OFFSET — BBA2 RC Calibration value offset
  [9] ADC_RCCAL_DIS — ADC RC Calibration Disable
    0=ADC RC Calibration is enabled; 1=ADC RC Calibration is disabled
  [8:4] ADC_RCCAL_MANUAL — ADC RC Calibration manual value
  [3:0] ADC_RCCAL_OFFSET — ADC RC Calibration value offset
0x1E4 RX_RCCAL_STAT ro reset 0x2104210 — RX RC Calibration Status
  [25:21] TZA_RCCAL — TZA RC Calibration
  [20:16] BBA_RCCAL — BBA RC Calibration
  [14:10] BBA2_RCCAL — BBA2 RC Calibration
  [9:5] ADC_RCCAL — ADC RC Calibration
  [4:0] RCCAL_CODE — RC Calibration code
0x1E8 AUXPLL_FCAL_CTRL reset 0x400000 — Aux PLL Frequency Calibration Control
  [22:16] DAC_CAL_ADJUST ro — Aux PLL DAC Calibration Adjust value
  [11:10] FCAL_SMP_DLY — Aux PLL Frequency Calibration Sample Delay
    {v}=The count signal is sampled {v+1} clk cycle after fcal_run signal is deasserted (v=0..3)
  [9] FCAL_COMP_INV — Aux PLL Frequency Calibration Comparison Invert
    0=(Default) The comparison associated with the count is not inverted; 1=The comparison associated with the count is inverted
  [8] FCAL_RUN_CNT — Aux PLL Frequency Calibration Run Count
    0=Run count is 256 clock cycles; 1=Run count is 512 clock cycles
  [7] AUXPLL_DAC_CAL_ADJUST_DIS — Aux PLL Frequency Calibration Disable
    0=Calibration is enabled; 1=Calibration is disabled
  [6:0] DAC_CAL_ADJUST_MANUAL — Aux PLL Frequency DAC Calibration Adjust Manual value
0x1EC AUXPLL_FCAL_CNT6 ro reset 0x0 — Aux PLL Frequency Calibration Count 6
  [25:16] FCAL_BESTDIFF — Aux PLL Frequency Calibration Best Difference
  [9:0] FCAL_COUNT_6 — Aux PLL Frequency Calibration Count 6
0x1F0 AUXPLL_FCAL_CNT5_4 ro reset 0x0 — Aux PLL Frequency Calibration Count 5 and 4
  [25:16] FCAL_COUNT_5 — Aux PLL Frequency Calibration Count 5
  [9:0] FCAL_COUNT_4 — Aux PLL Frequency Calibration Count 4
0x1F4 AUXPLL_FCAL_CNT3_2 ro reset 0x0 — Aux PLL Frequency Calibration Count 3 and 2
  [25:16] FCAL_COUNT_3 — Aux PLL Frequency Calibration Count 3
  [9:0] FCAL_COUNT_2 — Aux PLL Frequency Calibration Count 2
0x1F8 AUXPLL_FCAL_CNT1_0 ro reset 0x0 — Aux PLL Frequency Calibration Count 1 and 0
  [25:16] FCAL_COUNT_1 — Frequency Calibration Count 1
  [9:0] FCAL_COUNT_0 — Frequency Calibration Count 0
0x1FC RXDIG_DFT reset 0x8500
  [15] SRC_OUT_VLD_DLY_EN — SRC Out Valid Delay Enable
  [14] HI_RES_PH_EN — Hi Resolution Phase Enable
  [13:12] PH_MUX_SEL — DMA DTEST Phase Mux Select
    0=Wideband Phase; 1=Narrowband Phase; 2=Hi Resolution Phase
  [11:8] IQ_MUX_SEL — DMA DTEST IQ Mux Select
    0=Decimation filter I/Q output; 1=IQMC I/Q output; 2=DCOC I/Q output; 3=Channel filter I/Q output; 4=SRC I/Q output; 5=DC Residual I/Q output; 6=Sample Buffer I/Q output; 7=CFO Mixer I/Q output; 8=Demod Channel filter I/Q output; 9=Frac Corr I/Q output; 10=DC Residual I/Q Correction (12 LSBs, includes 1 fractional bit)
0x200 RX_DIG_CTRL_DRS reset 0x0 — RX Digital Control DataRate1
  [7:4] RX_DEC_FILT_OSR — Decimation Filter Oversampling
    values as RX_DIG_CTRL.RX_DEC_FILT_OSR
0x204 AGC_CTRL_0_DRS reset 0x0 — AGC Control 0 DataRate1
  [31:24] AGC_DOWN_RSSI_THRESH — AGC DOWN RSSI Threshold
  [23:16] AGC_UP_RSSI_THRESH — AGC UP RSSI Threshold
  [15:8] BBA_GAIN_SETTLE_TIME
  [7:0] LNA_GAIN_SETTLE_TIME
0x208 AGC_CTRL_1_DRS reset 0x0 — AGC Control 1 DataRate1
  [26] AGC_UP_SRC — AGC Up Source
    0=PDET LO; 1=RSSI
  [25:24] SLOW_AGC_SRC — Slow AGC Source Selection
    values as AGC_CTRL_0.SLOW_AGC_SRC
  [21:16] AGC_FAST_EXPIRE
  [12:0] AGC_UNFREEZE_TIME
0x20C AGC_CTRL_2_DRS reset 0x55 — AGC Control 2 DataRate1
  [6:4] BBA_PDET_SEL_HI — BBA PDET Threshold High
    values as AGC_CTRL_2.BBA_PDET_SEL_HI
  [2:0] TZA_PDET_SEL_HI — TZA PDET Threshold High
    values as AGC_CTRL_2.TZA_PDET_SEL_HI
0x210 DCOC_CTRL_DRS reset 0x0 — DCOC Control DataRate1
  [18:16] DCOC_ALPHA_RADIUS_IDX — Alpha-R Scaling
    0=1; 1=1/2; 2=1/4; 3=1/8; 4=1/16; 5=1/32; 6=1/64
  [12:8] DCOC_CORR_DLY_ALT — DCOC Correction Delay Alternate
  [4:0] DCOC_CORR_DLY — DCOC Correction Delay
0x214 DC_RESID_CTRL_DRS reset 0x0 — DC Residual Control DataRate1
  [28:20] DC_RESID_NWIN2 — DC Residual NWIN, for Second Run
  [18:16] DC_RESID_DLY — DC Residual Delay
  [6:0] DC_RESID_NWIN — DC Residual NWIN
0x220 RX_CHF_COEF_0_DRS reset 0x0 — Receive Channel Filter Coefficient 0 DataRate1
  [5:0] RX_CH_FILT_H0 — RX Channel Filter Coefficient 0
0x224 RX_CHF_COEF_1_DRS reset 0x0 — Receive Channel Filter Coefficient 1 DataRate1
  [5:0] RX_CH_FILT_H1 — RX Channel Filter Coefficient 1
{0x220+4i} RX_CHF_COEF_{i}_DRS reset 0x0 (i=2..5) — Receive Channel Filter Coefficient {i} DataRate1
  [6:0] RX_CH_FILT_H{i} — RX Channel Filter Coefficient {i}
0x238 RX_CHF_COEF_6_DRS reset 0x0 — Receive Channel Filter Coefficient 6 DataRate1
  [7:0] RX_CH_FILT_H6 — RX Channel Filter Coefficient 6
0x23C RX_CHF_COEF_7_DRS reset 0x0 — Receive Channel Filter Coefficient 7 DataRate1
  [7:0] RX_CH_FILT_H7 — RX Channel Filter Coefficient 7
0x240 RX_CHF_COEF_8_DRS reset 0x0 — Receive Channel Filter Coefficient 8 DataRate1
  [8:0] RX_CH_FILT_H8 — RX Channel Filter Coefficient 8
0x244 RX_CHF_COEF_9_DRS reset 0x0 — Receive Channel Filter Coefficient 9 DataRate1
  [8:0] RX_CH_FILT_H9 — RX Channel Filter Coefficient 9
0x248 RX_CHF_COEF_10_DRS reset 0x0 — Receive Channel Filter Coefficient 10 DataRate1
  [9:0] RX_CH_FILT_H10 — RX Channel Filter Coefficient 10
0x24C RX_CHF_COEF_11_DRS reset 0x0 — Receive Channel Filter Coefficient 11 DataRate1
  [9:0] RX_CH_FILT_H11 — RX Channel Filter Coefficient 11
0x250 RX_D_CHF_COEF_0_DRS reset 0x0 — Receive Demod Channel Filter Coef 0
  [8:0] RX_D_CH_FILT_H0 — RX Demod Channel Filter Coefficient 0
0x254 RX_D_CHF_COEF_1_DRS reset 0x0 — Receive Demod Channel Filter Coef 1 DataRate1
  [8:0] RX_D_CH_FILT_H1 — RX Demod Channel Filter Coefficient 1
{0x250+4i} RX_D_CHF_COEF_{i}_DRS reset 0x0 (i=2..4) — Receive Demod Channel Filter Coef {i} DataRate1
  [9:0] RX_D_CH_FILT_H{i} — RX Demod Channel Filter Coefficient {i}
